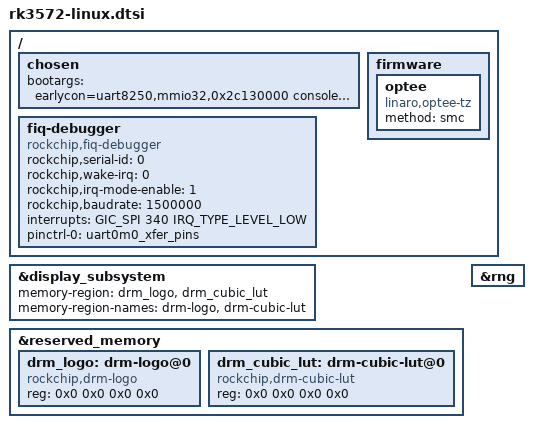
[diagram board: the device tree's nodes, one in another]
// SPDX-License-Identifier: (GPL-2.0+ OR MIT)
/*
 * Copyright (c) 2025 Rockchip Electronics Co., Ltd.
 *
 */

/ {
	chosen: chosen {
		bootargs = "earlycon=uart8250,mmio32,0x2c130000 console=ttyFIQ0 root=PARTUUID=614e0000-0000 rw rootwait rcupdate.rcu_expedited=1 rcu_nocbs=all";
	};

	fiq-debugger {
		compatible = "rockchip,fiq-debugger";
		rockchip,serial-id = <0>;
		rockchip,wake-irq = <0>;
		/* If enable uart uses irq instead of fiq */
		rockchip,irq-mode-enable = <1>;
		rockchip,baudrate = <1500000>;  /* Only 115200 and 1500000 */
		interrupts = <GIC_SPI 340 IRQ_TYPE_LEVEL_LOW>;
		pinctrl-names = "default";
		pinctrl-0 = <&uart0m0_xfer_pins>;
		status = "okay";
	};

	firmware {
		optee: optee {
			compatible = "linaro,optee-tz";
			method = "smc";
		};
	};
};

&display_subsystem {
	memory-region = <&drm_logo>, <&drm_cubic_lut>;
	memory-region-names = "drm-logo", "drm-cubic-lut";
	/* devfreq = <&dmc>; */
};

&reserved_memory {
	drm_logo: drm-logo@0 {
		compatible = "rockchip,drm-logo";
		reg = <0x0 0x0 0x0 0x0>;
	};

	drm_cubic_lut: drm-cubic-lut@0 {
		compatible = "rockchip,drm-cubic-lut";
		reg = <0x0 0x0 0x0 0x0>;
	};
};

&rng {
	status = "okay";
};
